# ETHSW register map
Registers are 32-bit, read-only, no defined reset value unless marked. A register's access mark holds for its fields unless they carry their own. Addresses are absolute; registers are grouped by the start of their names; [hi:lo] are bit positions; {n}, {i} and the like mark numbered series.

## VLAN
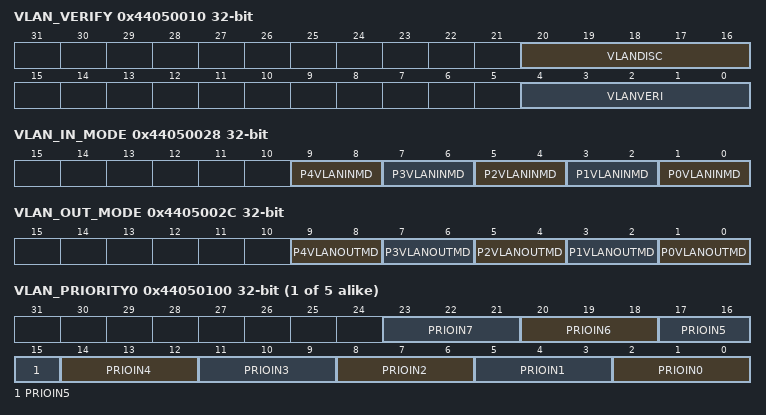
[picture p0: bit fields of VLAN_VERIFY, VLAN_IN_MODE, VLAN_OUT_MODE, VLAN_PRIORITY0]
0x44050010 VLAN_VERIFY access not given
  [20:16] VLANDISC, [4:0] VLANVERI
0x44050028 VLAN_IN_MODE access not given
  [2n+1:2n] P{n}VLANINMD (n=0..4)
0x4405002C VLAN_OUT_MODE access not given
  [2n+1:2n] P{n}VLANOUTMD (n=0..4)
0x44050030 VLAN_IN_MODE_ENA access not given
  [4:0] VLANINMDEN
0x44050034 VLAN_TAG_ID
  [15:0] VLANTAGID
{0x44050100+4i} VLAN_PRIORITY{i} access not given (i=0..4)
  [3n+2:3n] PRIOIN{n} (n=0..7)
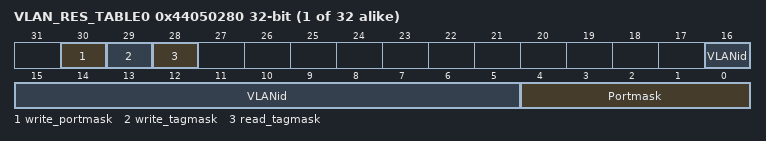
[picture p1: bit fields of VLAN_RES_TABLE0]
{0x44050280+4i} VLAN_RES_TABLE{i} access not given (i=0..31)
  [30] write_portmask, [29] write_tagmask, [28] read_tagmask, [16:5] VLANid, [4:0] Portmask

## BCAST
0x44050014 BCAST_DEFAULT_MASK access not given
  [4:0] BCASTDM
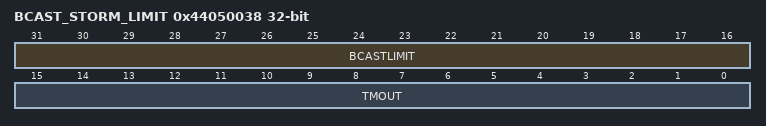
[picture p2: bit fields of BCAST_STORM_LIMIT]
0x44050038 BCAST_STORM_LIMIT access not given
  [31:16] BCASTLIMIT, [15:0] TMOUT

## MCAST
0x44050018 MCAST_DEFAULT_MASK access not given
  [4:0] MCASTDM
0x4405003C MCAST_STORM_LIMIT access not given
  [31:16] MCASTLIMIT

## MGMT
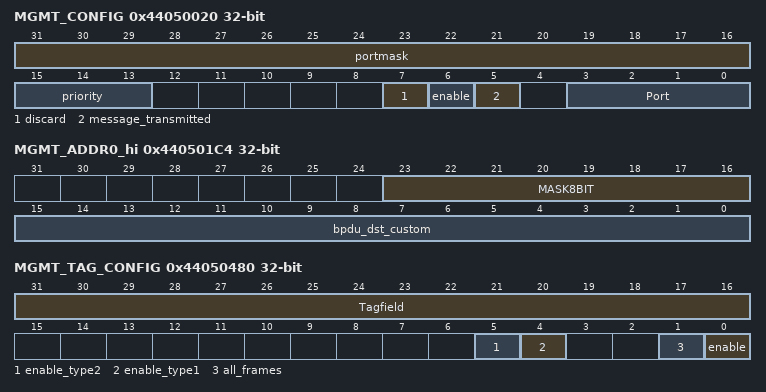
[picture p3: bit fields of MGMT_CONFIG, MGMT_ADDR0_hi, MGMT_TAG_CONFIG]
0x44050020 MGMT_CONFIG access not given
  [31:16] portmask, [15:13] priority, [7] discard, [6] enable, [5] message_transmitted, [3:0] Port
0x440501C0 MGMT_ADDR0_lo access not given
  [31:0] bpdu_dst_custom
0x440501C4 MGMT_ADDR0_hi access not given
  [23:16] MASK8BIT, [15:0] bpdu_dst_custom
0x44050480 MGMT_TAG_CONFIG access not given
  [31:16] Tagfield, [5] enable_type2, [4] enable_type1, [1] all_frames, [0] enable

## MIRROR
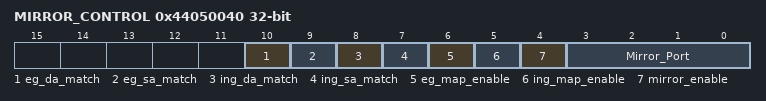
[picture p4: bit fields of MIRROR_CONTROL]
0x44050040 MIRROR_CONTROL access not given
  [10] eg_da_match, [9] eg_sa_match, [8] ing_da_match, [7] ing_sa_match, [6] eg_map_enable, [5] ing_map_enable, [4] mirror_enable, [3:0] Mirror_Port
0x44050044 MIRROR_EG_MAP access not given
  [4:0] EMAP
0x44050048 MIRROR_ING_MAP access not given
  [4:0] IMAP
0x4405004C MIRROR_ISRC_0 access not given
  [31:0] ISRC
0x44050050 MIRROR_ISRC_1 access not given
  [15:0] ISRC
0x44050054 MIRROR_IDST_0 access not given
  [31:0] IDST
0x44050058 MIRROR_IDST_1 access not given
  [15:0] IDST
0x4405005C MIRROR_ESRC_0 access not given
  [31:0] ESRC
0x44050060 MIRROR_ESRC_1 access not given
  [15:0] ESRC
0x44050064 MIRROR_EDST_0 access not given
  [31:0] EDST
0x44050068 MIRROR_EDST_1 access not given
  [15:0] EDST
0x4405006C MIRROR_CNT access not given
  [7:0] CNT

## QMGR
0x44050088 QMGR_ST_MINCELLS access not given
  [10:0] M_CELLS_MIN
0x44050094 QMGR_RED_MIN4 access not given
  [31:0] CFGRED_MINTH4
0x44050098 QMGR_RED_MAX4 access not given
  [31:0] CFGRED_MAXTH4
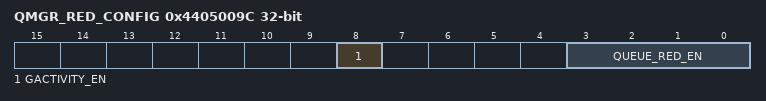
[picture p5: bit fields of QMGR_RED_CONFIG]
0x4405009C QMGR_RED_CONFIG access not given
  [8] GACTIVITY_EN, [3:0] QUEUE_RED_EN

## IMC
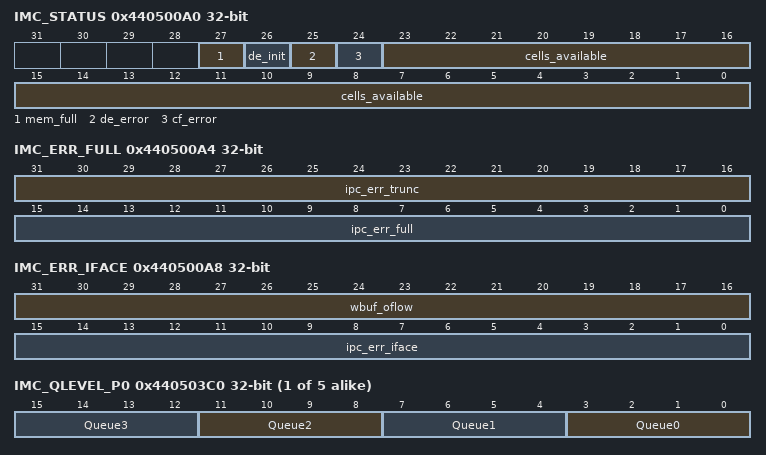
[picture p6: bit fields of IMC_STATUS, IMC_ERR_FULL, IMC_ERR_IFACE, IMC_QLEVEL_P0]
0x440500A0 IMC_STATUS
  [27] mem_full, [26] de_init, [25] de_error, [24] cf_error, [23:0] cells_available
0x440500A4 IMC_ERR_FULL
  [31:16] ipc_err_trunc, [15:0] ipc_err_full
0x440500A8 IMC_ERR_IFACE
  [31:16] wbuf_oflow, [15:0] ipc_err_iface
0x440500AC IMC_ERR_QOFLOW
  [15:0] op_error
0x440500B0 IMC_CONFIG access not given
  [0] wfq_enable
{0x440503C0+4i} IMC_QLEVEL_P{i} (i=0..4)
  [4n+3:4n] Queue{n} (n=0..3)

## IP
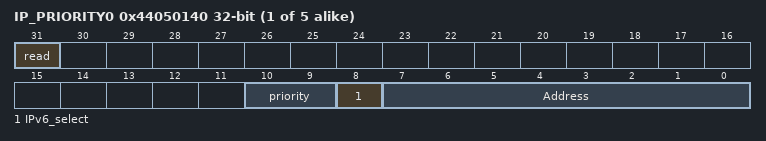
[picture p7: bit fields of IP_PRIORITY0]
{0x44050140+4i} IP_PRIORITY{i} access not given (i=0..4)
  [31] read, [10:9] priority, [8] IPv6_select, [7:0] Address

## PRIORITY
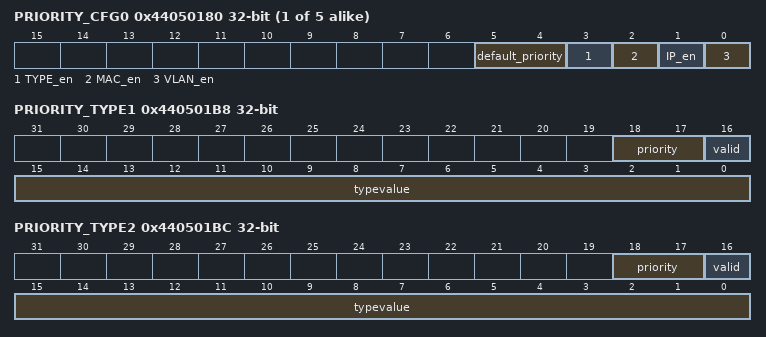
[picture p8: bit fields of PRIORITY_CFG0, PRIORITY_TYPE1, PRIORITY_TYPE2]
{0x44050180+4i} PRIORITY_CFG{i} access not given (i=0..4)
  [5:4] default_priority, [3] TYPE_en, [2] MAC_en, [1] IP_en, [0] VLAN_en
0x440501B8 PRIORITY_TYPE1 access not given
  [18:17] priority, [16] valid, [15:0] typevalue
0x440501BC PRIORITY_TYPE2 access not given
  [18:17] priority, [16] valid, [15:0] typevalue

## SYSTEM
{0x44050200+4i} SYSTEM_TAGINFO{i} access not given (i=0..4)
  [15:0] SYSVLANINFO

## AUTH
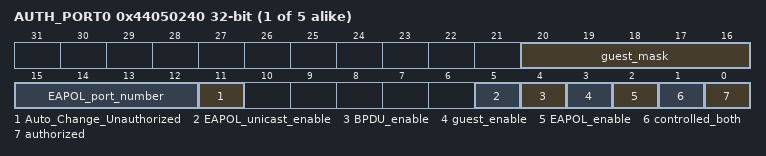
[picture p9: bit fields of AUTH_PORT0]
{0x44050240+4i} AUTH_PORT{i} access not given (i=0..4)
  [20:16] guest_mask, [15:12] EAPOL_port_number, [11] Auto_Change_Unauthorized, [5] EAPOL_unicast_enable, [4] BPDU_enable, [3] guest_enable, [2] EAPOL_enable, [1] controlled_both, [0] authorized
